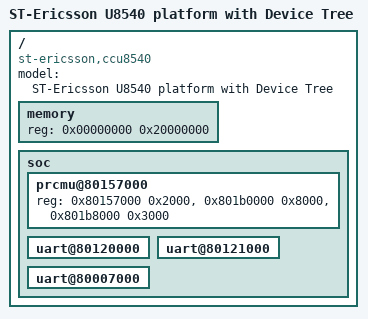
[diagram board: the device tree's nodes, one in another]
/*
 * Copyright 2013 ST-Ericsson AB
 *
 * The code contained herein is licensed under the GNU General Public
 * License. You may obtain a copy of the GNU General Public License
 * Version 2 or later at the following locations:
 *
 * http://www.opensource.org/licenses/gpl-license.html
 * http://www.gnu.org/copyleft/gpl.html
 */

/dts-v1/;
#include "dbx5x0.dtsi"

/ {
	model = "ST-Ericsson U8540 platform with Device Tree";
	compatible = "st-ericsson,ccu8540", "st-ericsson,u8540";

	memory {
		reg = <0x00000000 0x20000000>;
	};

	soc {
		prcmu@80157000 {
			reg = <0x80157000 0x2000>, <0x801b0000 0x8000>, <0x801b8000 0x3000>;
			reg-names = "prcmu", "prcmu-tcpm-per4", "prcmu-tcdm-per4";
		};

		uart@80120000 {
			status = "okay";
		};

		uart@80121000 {
			status = "okay";
		};

		uart@80007000 {
			status = "okay";
		};
	};
};
